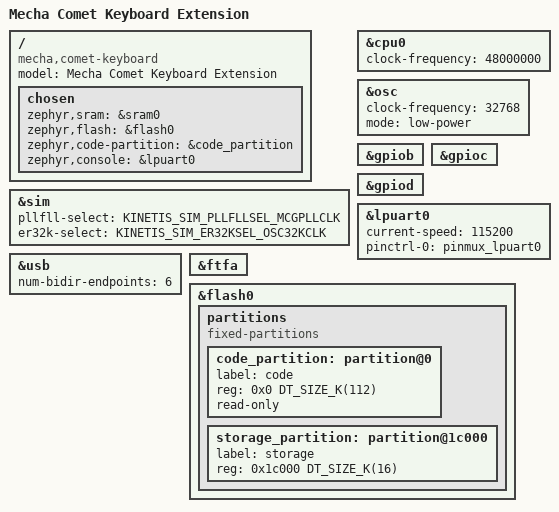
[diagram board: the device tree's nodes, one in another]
/*
 * Copyright (c) 2026 Mecha Systems
 *
 * SPDX-License-Identifier: BSD-3-Clause
 */

/dts-v1/;

#include <nxp/nxp_mcxc243.dtsi>
#include "mecha_comet_keyboard-pinctrl.dtsi"
#include "mecha_comet_keyboard-pointer.dtsi"
#include "mecha_comet_keyboard-leds.dtsi"
#include "mecha_comet_keyboard-layouts.dtsi"
#include "mecha_comet_keyboard-matrix.dtsi"
#include "mecha_comet_keyboard-rgb.dtsi"

/ {
    model = "Mecha Comet Keyboard Extension";
    compatible = "mecha,comet-keyboard", "nxp,mcxc243", "nxp,mcx";

    chosen {
        zephyr,sram = &sram0;
        zephyr,flash = &flash0;
        zephyr,code-partition = &code_partition;
        zephyr,console = &lpuart0;
    };
};

&sim {
    pllfll-select = <KINETIS_SIM_PLLFLLSEL_MCGPLLCLK>;
    er32k-select = <KINETIS_SIM_ER32KSEL_OSC32KCLK>;
};

&cpu0 {
    clock-frequency = <48000000>;
};

/* 32.768 kHz crystal on EXTAL0/XTAL0 */
&osc {
    clock-frequency = <32768>;
    mode = "low-power";
};

&gpiob {
    status = "okay";
};

&gpioc {
    status = "okay";
};

&gpiod {
    status = "okay";
};

&lpuart0 {
    status = "okay";
    current-speed = <115200>;
    pinctrl-0 = <&pinmux_lpuart0>;
    pinctrl-names = "default";
};

/*
 * The USB driver only accepts odd endpoint indexes for IN and even ones for
 * OUT. The keyboard, the serial notification and the serial data endpoints are
 * IN, plus one OUT, so indexes 1, 3, 5 and 2 are needed: 6 is the minimum.
 * A second serial port needs 10.
 */
zephyr_udc0: &usb {
    status = "okay";
    num-bidir-endpoints = <6>;
};

&ftfa {
    status = "okay";
};

/* 128 KB flash: 112 KB code, 16 KB (16 sectors) for settings storage */
&flash0 {
    partitions {
        compatible = "fixed-partitions";
        #address-cells = <1>;
        #size-cells = <1>;

        code_partition: partition@0 {
            label = "code";
            reg = <0x0 DT_SIZE_K(112)>;
            read-only;
        };

        storage_partition: partition@1c000 {
            label = "storage";
            reg = <0x1c000 DT_SIZE_K(16)>;
        };
    };
};
